# wsoc_mac_enc_secure register map
Vendor: Texas Instruments
Peripheral module from a debugger description file (folder CC35X1E).
Registers are 32-bit, read-only, reset 0x0 unless marked. A register's access mark holds for its fields unless they carry their own. Offsets are as the file gives them; lines under a group give offsets from that group; [hi:lo] are bit positions; {n}, {i} and the like mark numbered series; 'fields as' and 'values as' point back to an identical list; <NAME> marks a mode.

## wsoc_mac_enc_secure
0x00 enc_cfg access per field reset not defined
  [24] FORCE_GET_KEY rw — 0: FSM will go to GET_KEY only if "key_changed" 1: force GET_KEY even if not "key_changed"
  [20] AES_BYTE_REV rw — when set the mic bytes going to the aes engine (Rx) will be reversed in order
  [1] AAD_USE_HT_ORDER_BIT rw — when set, bit[15] in the mac header field controlled will be used. other wise it wil be masked.
  [0] MEM_ABORT_TX_MASK_DISABLE rw — When MAC-ENC recieve Abort from PMAC-Rx, It mask this abort in case of Tx operation. When this bit is set to '1', the Abort-Tx-Mask is disabled, so Abort will also be functional while Tx.
  [0] MEM_ENC_CMD_BUF_CLR_PULSE wo — When WR '1' to this Register - it generate a Pulse to Clear the ENC_CMD Buffers. It is WRCL MMR, for value back to '1' one cycly after the WR cycle.
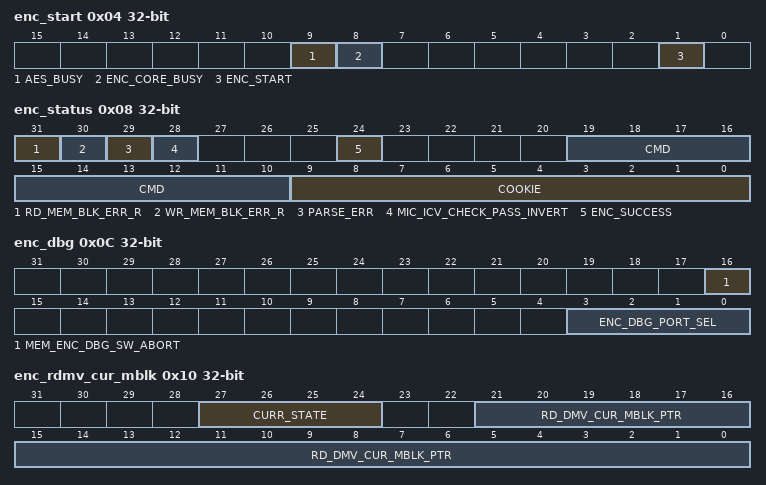
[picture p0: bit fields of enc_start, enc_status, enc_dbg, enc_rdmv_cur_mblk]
0x04 enc_start access not given reset not defined
  [9] AES_BUSY ro — when value is 1, AES encryption core is running
  [8] ENC_CORE_BUSY ro — when value is 1, encryption core is running
  [1] ENC_START ro — HW start signal. asserted by the FSM. asserted high until machine is done.
0x08 enc_status reset not defined — status of operation. equals to last status pushed to status fifo. status returns parse_err on reset because no command is loaded. this status does not enter the status fifo.
  [31] RD_MEM_BLK_ERR_R — set when one of the machines reached list end unexpectedly when trying to read from the packet RAM
  [30] WR_MEM_BLK_ERR_R — set when one of the machines reached list end unexpectedly when trying to write to the packet RAM
  [29] PARSE_ERR — if cmd filed doesnt match one of the engines, read value is 1.
  [28] MIC_ICV_CHECK_PASS_INVERT — if mic or icv check passed, read value is 0.
  [24] ENC_SUCCESS — when set, operation ended successfully.
  [19:10] CMD — command value of current loaded command
  [9:0] COOKIE — cookie value of current loaded command
0x0C enc_dbg access per field — select the output debug port.
  [16] MEM_ENC_DBG_SW_ABORT rw — When set to '1' performe ABORT to all MAC-ENC module: bith for Rx and Tx. After some duration, user/SW should clr this bit to '0'.
  [3:0] ENC_DBG_PORT_SEL rw
0x10 enc_rdmv_cur_mblk — current treated mem block pointer (dword aligned)
  [27:24] CURR_STATE — enc machine state machine.
  [21:0] RD_DMV_CUR_MBLK_PTR — mem block pointer. dword aligned
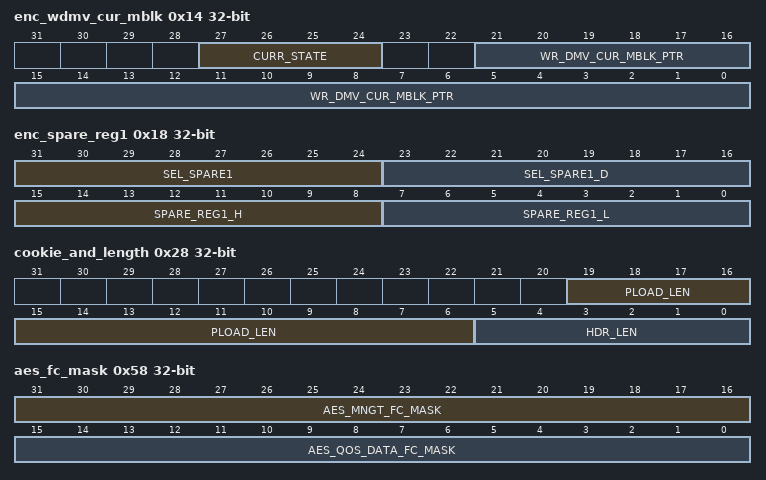
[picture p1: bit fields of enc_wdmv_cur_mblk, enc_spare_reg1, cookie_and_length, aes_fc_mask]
0x14 enc_wdmv_cur_mblk — current treated mem block pointer (dword aligned)
  [27:24] CURR_STATE — enc machine state machine.
  [21:0] WR_DMV_CUR_MBLK_PTR — mem block pointer. dword aligned
0x18 enc_spare_reg1 access per field reset not defined — spare bits for future use.
  [31:24] SEL_SPARE1 ro — decoded one hot value of spare_reg1_l[2:0].
  [23:16] SEL_SPARE1_D ro — sampled value of sel_spare1
  [15:8] SPARE_REG1_H rw
  [7:0] SPARE_REG1_L rw
0x1C enc_spare_reg2 access per field — spare bits for future use.
  [7:0] SPARE_REG2 rw
0x20 enc_curr_status access not given
  [2:0] CURR_STATE ro
0x24 key_ptr_frag_and_command — command field. fragment number(for Tx) and contains the key pointer and the command word.
  [23:0] KEY_PTR — key pointer, full address
0x28 cookie_and_length — command field. contains the cookie, header length and payload length.
  [19:6] PLOAD_LEN — payload length in bytes
  [5:0] HDR_LEN — mac header length in bytes
0x2C wr_cmd_error_status rw
  [2:0] WR_CMD_ERROR_STATUS_WROPT — error in time sequence of cmd1_valid_pulse and cmd2_valid_pulse [0] cmd1 received while waiting for cmd2 [1] cmd2 received before cmd1 [2] command fifo overflow
0x30 enc_key1 wo — Contains the key for the encryption engines. loaded by the encryption machine. For AES and TKIP and WAPI will contain the actual key. For WEP, bits[6:0] will be used for wep_key_len field.
  [31:0] ENC_KEY_31_0
{0x2C+4i} enc_key{i} wo (i=2..4) — Contains the key for the encryption engines. loaded by the encryption machine.
  [31:0] ENC_KEY_{32i-1}_{32i-32}
{0x3C+4i} shared_dec_mic{i} rw (i=1..4) — Contains the mic value for the WAPI decryption. loaded by the encryption machine.
  [31:0] SHARED_MIC_{32i-1}_{32i-32}
0x50 prev_key_ptr access per field — contains the saved key_ptr from previous command. used for wapi key calculation. key is latched when the encryption machine is done with an operation
  [21:0] PREV_KEY_PTR rw
0x54 aes_qos_ctrl_mask access per field reset not defined
  [15:0] AES_QOS_CTRL_MASK rw
0x58 aes_fc_mask rw reset not defined
  [31:16] AES_MNGT_FC_MASK, [15:0] AES_QOS_DATA_FC_MASK
0x5C aes_fc_mask_2 access per field reset not defined
  [15:0] AES_OTHER_FC_MASK rw
{0x5C+4i} aes_nonce{i} (i=1..3) — nonce field for the AES engine. calculated by HW.
  [31:0] SHARED_NONCE_{32i-1}_{32i-32}
0x6C aes_nonce4 reset 0x1000000 — nonce field for the AES engine. calculated by HW.
  [31:0] SHARED_NONCE_127_96
0x70 aes_asso1 — value calculated by HW.
  [31:0] AES_ASSO1 — bits 31:0 of the asso data
0x74 aes_asso2 — value calculated by HW.
  [31:0] AES_ASSO2 — bites 63:32 of the aes asso
0x78 aes_asso3 — value calculated by HW.
  [31:0] AES_ASSO3 — bits 95:64 of the aes_asso
0x7C aes_asso4 — value calculated by HW.
  [31:0] AES_ASSO4 — bits 127:96 of the aes_asso
{0x7C+4i} aes_aad{i} (i=1..8) — value calculated by HW.
  [31:0] AES_AAD_FULL{i} — bits {32i-1}:{32i-32} of the aad
0xA0 aes_header_len access per field
  [5:0] AES_HEADER_LEN rw
0xA4 fips_test_mode access per field — Configurate mode of operation: FIPS_NONE = 0 (Functional). FIPS_ECB = 1 (Test ECB Vectors). FIPS_CCM = 2 (Test CCM Vectors).
  [1:0] FIPS_TEST_MODE rw
{0xA4+4i} fips_enc_key{i} wo (i=1..4)
{0xB4+4i} fips_data_in_{i} rw (i=1..4)
{0xC4+4i} fips_data_out_{i} (i=1..4)
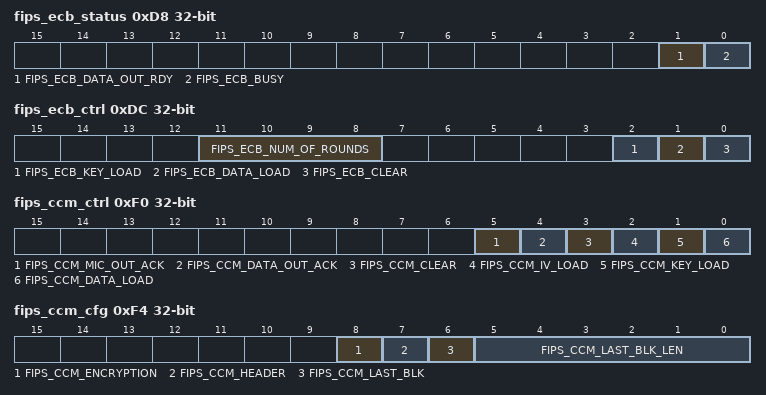
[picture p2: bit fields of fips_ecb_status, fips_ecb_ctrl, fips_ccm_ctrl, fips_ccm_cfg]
0xD8 fips_ecb_status
  [1] FIPS_ECB_DATA_OUT_RDY — signal which indicates data out is ready to be sampled - level signal
  [0] FIPS_ECB_BUSY — signal which indicates AES algorithm is in progress
0xDC fips_ecb_ctrl access per field
  [11:8] FIPS_ECB_NUM_OF_ROUNDS rw — configuration input, indicates the number of rounds to do.
  [2] FIPS_ECB_KEY_LOAD wo — enable pulse which indicate valid key_in.
  [1] FIPS_ECB_DATA_LOAD wo — enable pulse which indicate valid data_in
  [0] FIPS_ECB_CLEAR wo — control signal which stops the AES operation and return the AES to the IDLE mode
{0xDC+4i} fips_ccm_nonce_{i}_in rw (i=1..3)
0xEC fips_ccm_nonce_4_in access per field
  [7:0] FIPS_CCM_NONCE_4_IN rw
0xF0 fips_ccm_ctrl access per field
  [5] FIPS_CCM_MIC_OUT_ACK wo, [4] FIPS_CCM_DATA_OUT_ACK wo, [3] FIPS_CCM_CLEAR wo, [2] FIPS_CCM_IV_LOAD wo, [1] FIPS_CCM_KEY_LOAD wo, [0] FIPS_CCM_DATA_LOAD wo
0xF4 fips_ccm_cfg access per field
  [8] FIPS_CCM_ENCRYPTION rw, [7] FIPS_CCM_HEADER rw, [6] FIPS_CCM_LAST_BLK rw, [5:0] FIPS_CCM_LAST_BLK_LEN rw
0xF8 fips_ccm_cfg_2 access per field
  [15:0] FIPS_CCM_PLOAD_LEN rw
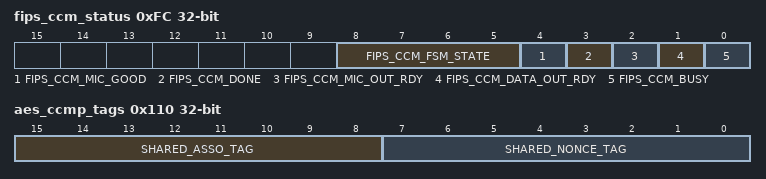
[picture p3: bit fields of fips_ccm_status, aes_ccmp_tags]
0xFC fips_ccm_status
  [8:5] FIPS_CCM_FSM_STATE, [4] FIPS_CCM_MIC_GOOD, [3] FIPS_CCM_DONE, [2] FIPS_CCM_MIC_OUT_RDY, [1] FIPS_CCM_DATA_OUT_RDY, [0] FIPS_CCM_BUSY
0x100 fips_ccm_mic_out_1
0x104 fips_ccm_mic_out_2
0x108 fips_ccm_mic_in_1 rw
0x10C fips_ccm_mic_in_2 rw
0x110 aes_ccmp_tags access per field reset not defined
  [15:8] SHARED_ASSO_TAG rw, [7:0] SHARED_NONCE_TAG rw
0x114 local_mac_addr1 wo — Contains the local mac address, used to override the address from source packet
  [31:0] LOCAL_MAC_ADDR_31_0
0x118 local_mac_addr2 access per field — Contains the local mac address, used to override the address from source packet
  [15:0] LOCAL_MAC_ADDR_47_32 wo
0x11C peer_mac_addr1 access per field — Contains the local mac address, used to override the address from source packet
  [15:0] LOCAL_MAC_ADDR_31_0 wo
0x120 peer_mac_addr2 wo — Contains the local mac address, used to override the address from source packet
  [31:0] PEER_MAC_ADDR_47_32
